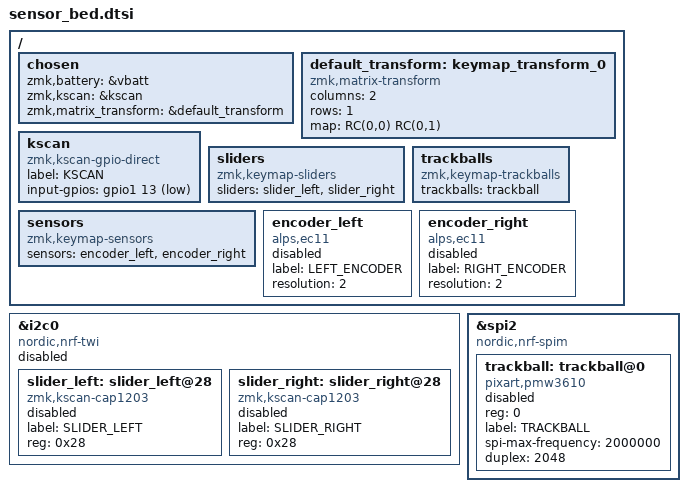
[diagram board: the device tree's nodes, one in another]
/*
 * Copyright (c) 2020 The ZMK Contributors
 *
 * SPDX-License-Identifier: MIT
 */

#include <dt-bindings/zmk/matrix_transform.h>

/* blade-specific: common settings */ 
/ {

	chosen: chosen {
		zmk,battery = &vbatt;
		zmk,kscan = &kscan;
		zmk,matrix_transform = &default_transform;
	};

/* global matrix transform */
	default_transform: keymap_transform_0 {
		compatible = "zmk,matrix-transform";
		columns = <2>;
		rows = <1>;
		map = <
          RC(0,0) RC(0,1)
		>;

	};

  /* Scan matrix declaration */
	kscan: kscan {
		compatible = "zmk,kscan-gpio-direct";
		label = "KSCAN";

		input-gpios
	  = <&gpio1 13 (GPIO_ACTIVE_LOW | GPIO_PULL_UP)>
    ;
	};

  /* Configure sliders (both split can have a slider) */
	sliders {
		compatible = "zmk,keymap-sliders";
		sliders = <&slider_left &slider_right>;
	};

  /* Configure trackballs (either split can have the trackball) */
	trackballs {
		compatible = "zmk,keymap-trackballs";
		trackballs = <&trackball>;
	};

  /* Configure encoders (both splits can have a encoder) */
	sensors {
		compatible = "zmk,keymap-sensors";
		sensors = <&encoder_left &encoder_right>;
	};
  
  // define the two encoders
	encoder_left: encoder_left {
		compatible = "alps,ec11";
    status = "disabled";
		label = "LEFT_ENCODER";
		resolution = <2>;
	};

	encoder_right: encoder_right {
		compatible = "alps,ec11";
    status = "disabled";
		label = "RIGHT_ENCODER";
    resolution = <2>;
	};
};

/* Declare the two sliders */
&i2c0 {
  compatible = "nordic,nrf-twi";
  status = "disabled";


  slider_left: slider_left@28 {
	  compatible = "zmk,kscan-cap1203";
	  label = "SLIDER_LEFT";
    status = "disabled";
    reg = <0x28>;
  };

  slider_right: slider_right@28 {
	  compatible = "zmk,kscan-cap1203";
	  label = "SLIDER_RIGHT";
    status = "disabled";
    reg = <0x28>;
  };

};

/* Declare the trackball */
&spi2 {
  compatible = "nordic,nrf-spim";

  trackball: trackball@0 {
    compatible = "pixart,pmw3610";
    status = "disabled";
    reg = <0>;
    label = "TRACKBALL";
    spi-max-frequency = <2000000>;
    duplex = <2048>; // required by 3-wire spi
  };
};
